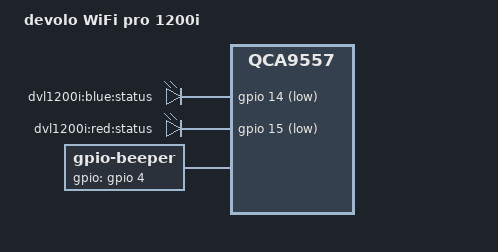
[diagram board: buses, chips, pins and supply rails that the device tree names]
// SPDX-License-Identifier: GPL-2.0-or-later OR MIT
/dts-v1/;

#include <dt-bindings/gpio/gpio.h>
#include <dt-bindings/input/input.h>

#include "qca9558_devolo_dvl1xxx.dtsi"

/ {
	compatible = "devolo,dvl1200i", "qca,qca9557";
	model = "devolo WiFi pro 1200i";

	aliases {
		led-boot = &status_blue;
		led-failsafe = &status_red;
		led-running = &status_blue;
		led-upgrade = &status_red;
	};

	leds {
		compatible = "gpio-leds";

		status_blue: status_blue {
			label = "dvl1200i:blue:status";
			gpios = <&gpio 14 GPIO_ACTIVE_LOW>;
			default-state = "on";
		};

		status_red: status_red {
			label = "dvl1200i:red:status";
			gpios = <&gpio 15 GPIO_ACTIVE_LOW>;
		};
	};

	beeper {
		compatible = "gpio-beeper";
		gpios = <&gpio 4 GPIO_ACTIVE_HIGH>;
	};
};

&eth0 {
	pll-data = <0xbe000000 0x80000101 0x80001313>;
};

&gmac_config {
	rxdv-delay = <3>;
	rxd-delay = <3>;
	txen-delay = <3>;
	txd-delay = <3>;
	rgmii-enabled = <1>;
};
